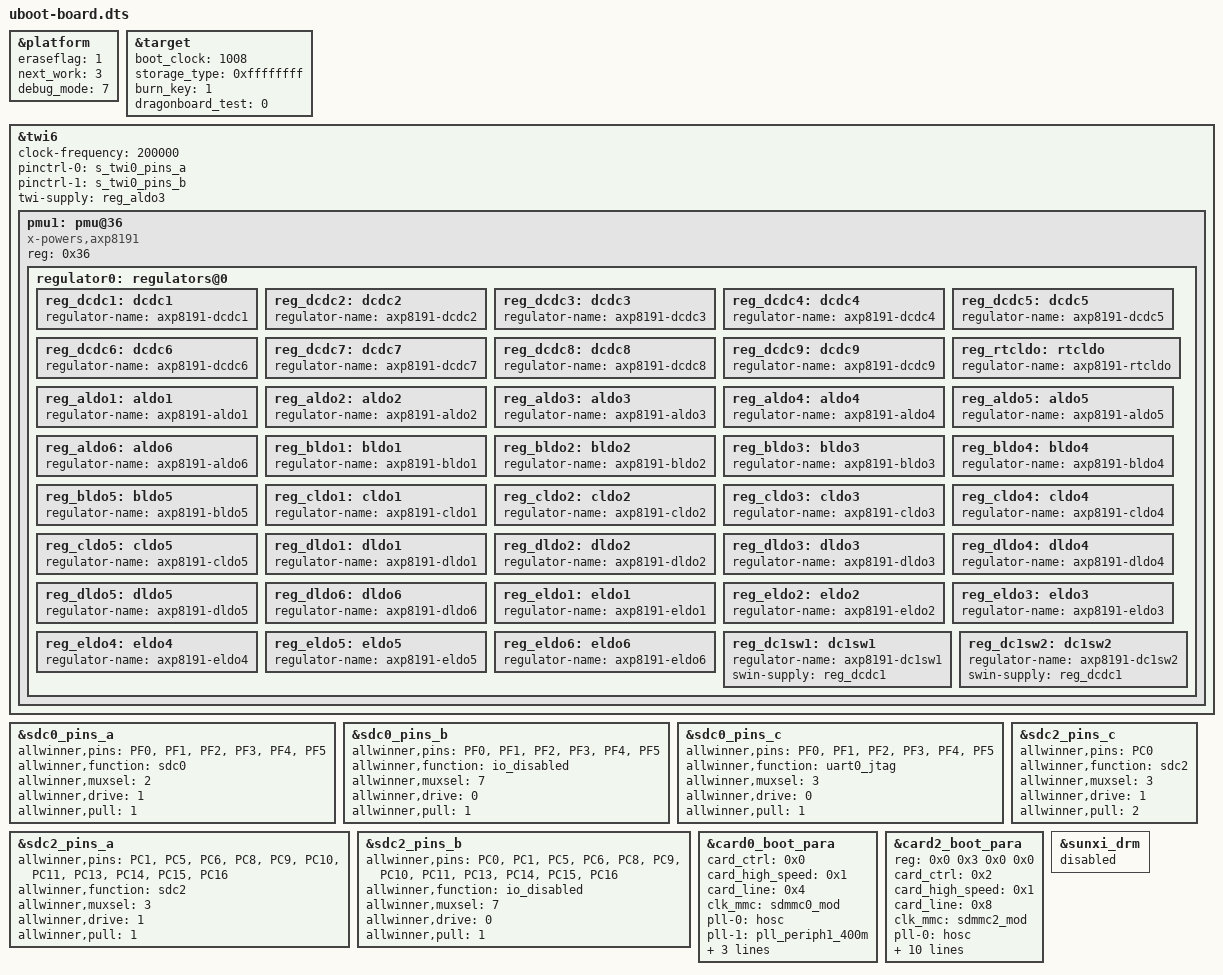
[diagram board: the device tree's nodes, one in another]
/*
 * Allwinner Technology CO., Ltd. sun60iw2p1 soc board.
 *
 * soc board support.
 */

&platform {
	eraseflag   = <1>;
	next_work   = <3>;
	debug_mode  = <7>;
};

&target {
	boot_clock = <1008>;	/*CPU boot frequency, Unit: MHz*/
	storage_type = <0xffffffff>; /*boot medium, 0-nand, 1-card0, 2-card2, -1(defualt)auto scan*/
	burn_key = <1>;		/*1:support burn key; 0:not support burn key*/
	dragonboard_test = <0>;	/*1:support card boot dragonboard; 0:not support card boot dragonboard*/
};

&twi6 {
	clock-frequency = <200000>;
	pinctrl-0 = <&s_twi0_pins_a>;
	pinctrl-1 = <&s_twi0_pins_b>;
	twi-supply = <&reg_aldo3>;
	status = "okay";
	pmu1: pmu@36 {
		compatible = "x-powers,axp8191";
		reg = <0x36>;
		status = "okay";

		regulator0: regulators@0 {
			reg_dcdc1: dcdc1 {
				regulator-name = "axp8191-dcdc1";
			};
			reg_dcdc2: dcdc2 {
				regulator-name = "axp8191-dcdc2";
			};
			reg_dcdc3: dcdc3 {
				regulator-name = "axp8191-dcdc3";
			};
			reg_dcdc4: dcdc4 {
				regulator-name = "axp8191-dcdc4";
			};
			reg_dcdc5: dcdc5 {
				regulator-name = "axp8191-dcdc5";
			};
			reg_dcdc6: dcdc6 {
				regulator-name = "axp8191-dcdc6";
			};
			reg_dcdc7: dcdc7 {
				regulator-name = "axp8191-dcdc7";
			};
			reg_dcdc8: dcdc8 {
				regulator-name = "axp8191-dcdc8";
			};
			reg_dcdc9: dcdc9 {
				regulator-name = "axp8191-dcdc9";
			};
			reg_rtcldo: rtcldo {
				regulator-name = "axp8191-rtcldo";
			};
			reg_aldo1: aldo1 {
				regulator-name = "axp8191-aldo1";
			};
			reg_aldo2: aldo2 {
				regulator-name = "axp8191-aldo2";
			};
			reg_aldo3: aldo3 {
				regulator-name = "axp8191-aldo3";
			};
			reg_aldo4: aldo4 {
				regulator-name = "axp8191-aldo4";
			};
			reg_aldo5: aldo5 {
				regulator-name = "axp8191-aldo5";
			};
			reg_aldo6: aldo6 {
				regulator-name = "axp8191-aldo6";
			};
			reg_bldo1: bldo1 {
				regulator-name = "axp8191-bldo1";
			};
			reg_bldo2: bldo2 {
				regulator-name = "axp8191-bldo2";
			};
			reg_bldo3: bldo3 {
				regulator-name = "axp8191-bldo3";
			};
			reg_bldo4: bldo4 {
				regulator-name = "axp8191-bldo4";
			};
			reg_bldo5: bldo5 {
				regulator-name = "axp8191-bldo5";
			};
			reg_cldo1: cldo1 {
				regulator-name = "axp8191-cldo1";
			};
			reg_cldo2: cldo2 {
				regulator-name = "axp8191-cldo2";
			};
			reg_cldo3: cldo3 {
				regulator-name = "axp8191-cldo3";
			};
			reg_cldo4: cldo4 {
				regulator-name = "axp8191-cldo4";
			};
			reg_cldo5: cldo5 {
				regulator-name = "axp8191-cldo5";
			};
			reg_dldo1: dldo1 {
				regulator-name = "axp8191-dldo1";
			};
			reg_dldo2: dldo2 {
				regulator-name = "axp8191-dldo2";
			};
			reg_dldo3: dldo3 {
				regulator-name = "axp8191-dldo3";
			};
			reg_dldo4: dldo4 {
				regulator-name = "axp8191-dldo4";
			};
			reg_dldo5: dldo5 {
				regulator-name = "axp8191-dldo5";
			};
			reg_dldo6: dldo6 {
				regulator-name = "axp8191-dldo6";
			};
			reg_eldo1: eldo1 {
				regulator-name = "axp8191-eldo1";
			};
			reg_eldo2: eldo2 {
				regulator-name = "axp8191-eldo2";
			};
			reg_eldo3: eldo3 {
				regulator-name = "axp8191-eldo3";
			};
			reg_eldo4: eldo4 {
				regulator-name = "axp8191-eldo4";
			};
			reg_eldo5: eldo5 {
				regulator-name = "axp8191-eldo5";
			};
			reg_eldo6: eldo6 {
				regulator-name = "axp8191-eldo6";
			};
			reg_dc1sw1: dc1sw1 {
				regulator-name = "axp8191-dc1sw1";
				swin-supply = <&reg_dcdc1>;
			};
			reg_dc1sw2: dc1sw2 {
				regulator-name = "axp8191-dc1sw2";
				swin-supply = <&reg_dcdc1>;
			};
		};
	};
};

&sdc0_pins_a {
		allwinner,pins = "PF0", "PF1", "PF2",
				 "PF3", "PF4", "PF5";
		allwinner,function = "sdc0";
		allwinner,muxsel = <2>;
		allwinner,drive = <1>;
		allwinner,pull = <1>;
};

&sdc0_pins_b {
		allwinner,pins = "PF0", "PF1", "PF2",
				 "PF3", "PF4", "PF5";
		allwinner,function = "io_disabled";
		allwinner,muxsel = <7>;
		allwinner,drive = <0>;
		allwinner,pull = <1>;
};

&sdc0_pins_c {
		allwinner,pins = "PF0", "PF1", "PF2",
		  		 "PF3", "PF4", "PF5";
		allwinner,function = "uart0_jtag";
		allwinner,muxsel = <3>;
		allwinner,drive = <0>;
		allwinner,pull = <1>;
};


&sdc2_pins_a {
		allwinner,pins = "PC1", "PC5", "PC6",
				 "PC8", "PC9", "PC10", "PC11",
				 "PC13", "PC14", "PC15", "PC16";
		allwinner,function = "sdc2";
		allwinner,muxsel = <3>;
		allwinner,drive = <1>;
		allwinner,pull = <1>;
};

&sdc2_pins_b {
		allwinner,pins = "PC0", "PC1", "PC5", "PC6",
				 "PC8", "PC9", "PC10", "PC11",
				 "PC13", "PC14", "PC15", "PC16";
		allwinner,function = "io_disabled";
		allwinner,muxsel = <7>;
		allwinner,drive = <0>;
		allwinner,pull = <1>;
};

&sdc2_pins_c {
		allwinner,pins = "PC0";
		allwinner,function = "sdc2";
		allwinner,muxsel = <3>;
		allwinner,drive = <1>;
		allwinner,pull = <2>;
};

&card0_boot_para {
		/* Avoid dtc compiling warnings. @TODO: Developer should modify this to the actual value */
		/* reg = <0x0 0x2 0x0 0x0>;  [> Avoid dtc compiling warnings. @TODO: Developer should modify this to the actual value <] */
	device_type = "card0_boot_para";
	card_ctrl = <0x0>;
	card_high_speed = <0x1>;
	card_line = <0x4>;
	clk_mmc = "sdmmc0_mod";
	pll-0 = "hosc";
	pll-1 = "pll_periph1_400m";
	pll-2 = "pll_periph1_300m";
	pinctrl-0 = <&sdc0_pins_a>;
	clk_type = "typ1";
};

&card2_boot_para {
	/*
	* Avoid dtc compiling warnings.
	* @TODO: Developer should modify this to the actual value
	*/
	reg = <0x0 0x3 0x0 0x0>;
	device_type = "card2_boot_para";
	card_ctrl = <0x2>;
	card_high_speed = <0x1>;
	card_line = <0x8>;
	clk_mmc = "sdmmc2_mod";
	pll-0 = "hosc";
	pll-1 = "pll_periph1_800m";
	pll-2 = "pll_periph1_600m";
	pinctrl-0 = <&sdc2_pins_a &sdc2_pins_c>;
	sdc_ex_dly_used = <0x2>;
	sdc_tm4_hs200_max_freq = <150>;
	sdc_tm4_hs400_max_freq = <150>;
	sdc_tm4_win_th = <0x7>;
	sdc_io_1v8 = <0x1>;
	sdc_type = "tm4";
	clk_type = "typ1";
};

&sunxi_drm {
	status = "disabled";
};
